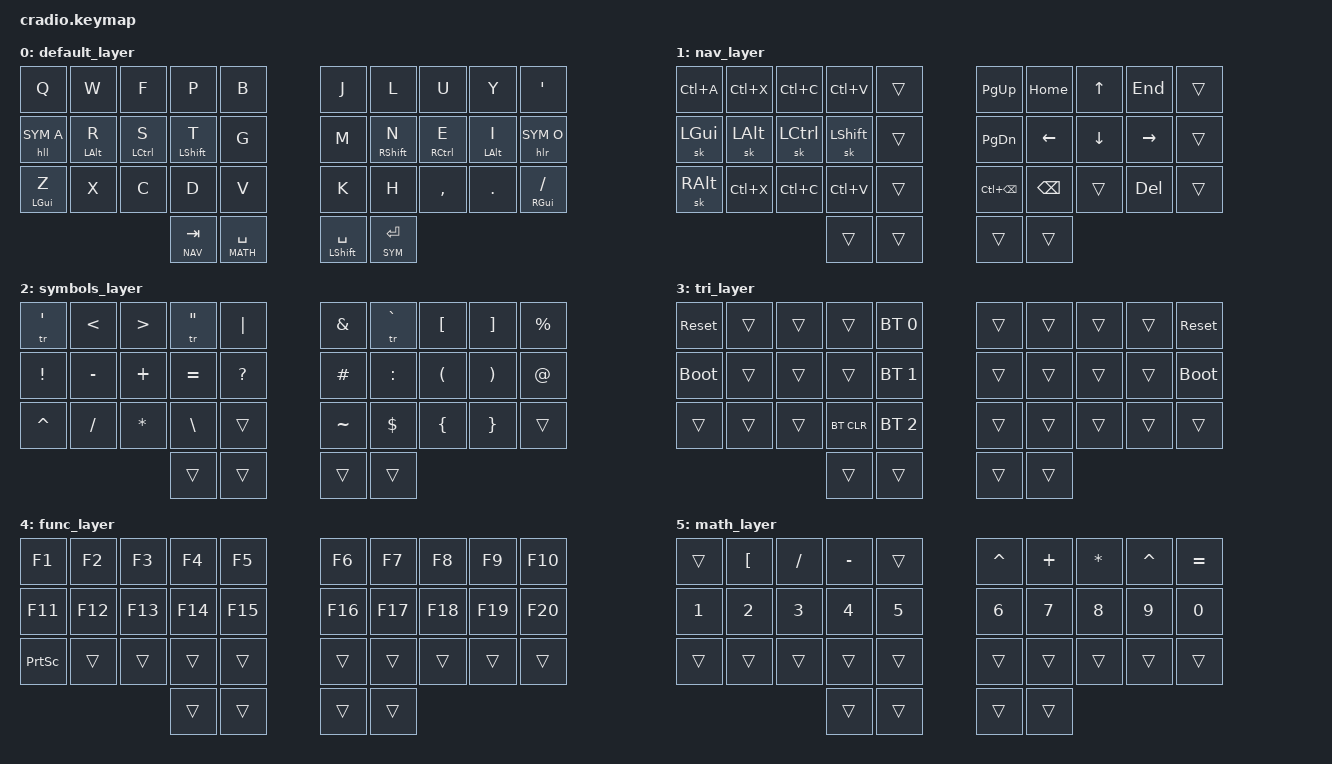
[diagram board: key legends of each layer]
// Copyright (c) 2022 The ZMK Contributors
// SPDX-License-Identifier: MIT

#include <behaviors.dtsi>
#include <dt-bindings/zmk/keys.h>
#include <dt-bindings/zmk/bt.h>
#include "timeless_hrm.keymap"
#include "zmk-helpers/key-labels/36.h" // Source key-labels.

// Home row mods macro
// #define HRML(k1,k2,k3,k4) &lt SYM   k1  &ht LALT k2  &ht LCTRL k3  &ht LSHFT k4
// #define HRMR(k1,k2,k3,k4) &ht RSHFT k1  &ht LCTRL k2  &ht LALT k3  &lt SYM k4
#define DEFAULT 0
#define NAV 1
#define SYM 2
#define TRI 3
#define FUNC 4
#define MATH 5

ZMK_COMBO(copy,  &kp LC(C), LB4 LB3)
ZMK_COMBO(paste, &kp LC(V), LB3 LB2)
ZMK_COMBO(cut, &kp LC(X), LB4 LB2)

ZMK_COMBO(esc, &kp ESC, LT3 LM3)
ZMK_COMBO(semi, &kp SEMI, RT4 RM4)
ZMK_COMBO(underscore, &kp LS(MINUS), LM3 LB3)

ZMK_COMBO(caps_wurd, &caps_word, LM1 RM1)

//ZMK_COMBO(lreset, &sys_reset, LT5 LT1)
//ZMK_COMBO(rreset, &sys_reset, RT1 RT5)

/ {
    conditional_layers {
        compatible = "zmk,conditional-layers";
        tri_layer {
            if-layers = <NAV SYM>;
            then-layer = <TRI>;
        };

        func_layer {
            if-layers = <NAV MATH>;
            then-layer = <FUNC>;
        };
    };

    // behaviors {
    //         sclh: underscore_slash {
    //             compatible = "zmk,behavior-mod-morph";
    //             #binding-cells = <0>;
    //             bindings = <LS(MINUS)>, <FSLH>;
    //             mods = <(MOD_LSFT|MOD_RSFT)>;
    //         };
    //     };

    macros {
        triple_repeat: triple_repeat {
            compatible = "zmk,behavior-macro";
            #binding-cells = <0>;
            wait-ms = <40>;
            tap-ms = <40>;
            bindings
                = <&macro_tap &key_repeat &key_repeat>;
        };

        tr: triple_ht {
            compatible = "zmk,behavior-hold-tap";
            #binding-cells = <2>;
            tapping-term-ms = <150>;
            flavor = "hold-preferred";
            bindings = <&kp>, <&triple_repeat>;
        };
    };

    keymap {
        compatible = "zmk,keymap";

        // 0
        default_layer {
            bindings = <
          //╭──────────┬──────────┬──────────┬──────────┬──────────╮   ╭──────────┬──────────┬──────────┬──────────┬──────────╮
          //│  Q       │  W       │  E       │  R       │  T       │   │  Y       │  U       │  I       │  O       │  P       │
          //├──────────┼──────────┼──────────┼──────────┼──────────┤   ├──────────┼──────────┼──────────┼──────────┼──────────┤
          //│  A       │  S       │  D       │  F       │  G       │   │  H       │  J       │  K       │  L       │ ' "      │
          //├──────────┼──────────┼──────────┼──────────┼──────────┤   ├──────────┼──────────┼──────────┼──────────┼──────────┤
          //│  Z       │  X       │  C       │  V       │  B       │   │  N       │  M       │ , <      │ . >      │ / ?      │
          //╰──────────┴──────────┴──────────┼──────────┼──────────┤   ├──────────┼──────────┼──────────┴──────────┴──────────╯
          //                                 |          |          |   |          |          |
          //                                 ╰──────────┴──────────╯   ╰──────────┴──────────╯
              &kp Q       &kp W        &kp F         &kp P         &kp B    &kp J   &kp L         &kp U         &kp Y        &kp APOS
              &hll SYM A  &hml LALT R  &hml LCTRL S  &hml LSHFT T  &kp G    &kp M   &hmr RSHFT N  &hmr RCTRL E  &hmr LALT I  &hlr SYM O
              &hml LGUI Z &kp X        &kp C         &kp D         &kp V    &kp K   &kp H         &kp COMMA     &kp DOT      &hmr RGUI FSLH
                                       &lt NAV TAB    &lt MATH SPACE        &mt LSHFT SPACE  &lt SYM ENTER
            >;
        };

        // 1
        nav_layer {
            bindings = <
          //╭──────────┬──────────┬──────────┬──────────┬──────────╮   ╭──────────┬──────────┬──────────┬──────────┬──────────╮
          //│ ALL      │  CUT     │  COPY    │  PASTE   │          │   │ HOME     │ PAGE DN  │ PAGE UP  │ END      │  :       │
          //├──────────┼──────────┼──────────┼──────────┼──────────┤   ├──────────┼──────────┼──────────┼──────────┼──────────┤
          //│ DELETE   │  4       │  5       │  6       │          │   │ LEFT     │ DOWN     │ UP       │ RIGHT    │  ;       │
          //├──────────┼──────────┼──────────┼──────────┼──────────┤   ├──────────┼──────────┼──────────┼──────────┼──────────┤
          //│ CAPS     │  7       │  8       │  9       │  0       │   │CTRL-BSPC │ BSPC     │          │ DEL      │          │
          //╰──────────┴──────────┴──────────┼──────────┼──────────┤   ├──────────┼──────────┼──────────┴──────────┴──────────╯
          //                                 |          |          |   |          |          |
          //                                 ╰──────────┴──────────╯   ╰──────────┴──────────╯
            &kp LC(A)   &kp LC(X)  &kp LC(C)  &kp LC(V)   &trans       &kp PG_UP    &kp HOME     &kp UP     &kp END     &trans
            &sk LGUI    &sk LALT   &sk LCTRL  &sk LSHFT   &trans       &kp PG_DN    &kp LEFT     &kp DOWN   &kp RIGHT   &trans
            &sk RALT    &kp LC(X)  &kp LC(C)  &kp LC(V)   &trans       &kp LC(BSPC) &kp BSPC     &trans     &kp DEL     &trans
                                              &trans      &trans       &trans       &trans
            >;
        };

        // 2
        symbols_layer {
            bindings = <
          //╭──────────┬──────────┬──────────┬──────────┬──────────╮   ╭──────────┬──────────┬──────────┬──────────┬──────────╮
          //│          │  [       │  {       │  }       │          │   │  ^       │  (       │  )       │  ]       │  ~       │
          //├──────────┼──────────┼──────────┼──────────┼──────────┤   ├──────────┼──────────┼──────────┼──────────┼──────────┤
          //│  !       │  @       │  #       │  $       │  %       │   │  *       │  -       │  =       │  \       │  `       │
          //├──────────┼──────────┼──────────┼──────────┼──────────┤   ├──────────┼──────────┼──────────┼──────────┼──────────┤
          //│          │          │          │          │          │   │  &       │  _       │  +       │  │       │          │
          //╰──────────┴──────────┴──────────┼──────────┼──────────┤   ├──────────┼──────────┼──────────┴──────────┴──────────╯
          //                                 |          |          |   |          |          |
          //                                 ╰──────────┴──────────╯   ╰──────────┴──────────╯
            &tr APOS    &kp LT      &kp GT     &tr DQT    &kp PIPE      &kp AMPERSAND   &tr GRAVE   &kp LBKT    &kp RBKT    &kp PERCENT
            &kp EXCL    &kp MINUS   &kp PLUS   &kp EQUAL  &kp QMARK     &kp HASH        &kp COLON   &kp LPAR    &kp RPAR    &kp AT_SIGN
            &kp CARET   &kp FSLH    &kp STAR   &kp BSLH   &trans        &kp TILDE       &kp DLLR    &kp LBRC    &kp RBRC    &trans
                                               &trans     &trans        &trans          &trans
            >;
        };

        // 3
        tri_layer {
            bindings = <
          //╭──────────┬──────────┬──────────┬──────────┬──────────╮   ╭──────────┬──────────┬──────────┬──────────┬──────────╮
          //│ RESET    │          │          │          │PROFILE 0 │   │          │          │          │          │  RESET   │
          //├──────────┼──────────┼──────────┼──────────┼──────────┤   ├──────────┼──────────┼──────────┼──────────┼──────────┤
          //│BOOTLOADER│          │          │          │PROFILE 1 │   │          │          │          │          │BOOTLOADER│
          //├──────────┼──────────┼──────────┼──────────┼──────────┤   ├──────────┼──────────┼──────────┼──────────┼──────────┤
          //│          │          │          │ CLEAR BT │PROFILE 2 │   │          │          │          │          │          │
          //╰──────────┴──────────┴──────────┼──────────┼──────────┤   ├──────────┼──────────┼──────────┴──────────┴──────────╯
          //                                 |          |          |   |          |          |
          //                                 ╰──────────┴──────────╯   ╰──────────┴──────────╯
            &sys_reset   &trans     &trans     &trans     &bt BT_SEL 0    &trans     &trans     &trans     &trans    &sys_reset
            &bootloader  &trans     &trans     &trans     &bt BT_SEL 1    &trans     &trans     &trans     &trans    &bootloader
            &trans       &trans     &trans    &bt BT_CLR  &bt BT_SEL 2    &trans     &trans     &trans     &trans    &trans
                                               &trans     &trans          &trans     &trans
            >;
        };

        // 4
        func_layer {
            bindings = <
            &kp F1      &kp F2      &kp F3      &kp F4      &kp F5      &kp  F6     &kp F7      &kp F8      &kp F9      &kp F10
            &kp F11     &kp F12     &kp F13     &kp F14     &kp F15     &kp  F16    &kp F17     &kp F18     &kp F19     &kp F20
            &kp PSCRN   &trans      &trans      &trans      &trans      &trans      &trans      &trans      &trans      &trans
                                                &trans      &trans      &trans      &trans
            >;
        };

        // 5
        math_layer {
            bindings = <
          //╭──────────┬──────────┬──────────┬──────────┬──────────╮   ╭──────────┬──────────┬──────────┬──────────┬──────────╮
          //│          │  [       │  {       │  }       │          │   │  ^       │  (       │  )       │  ]       │  ~       │
          //├──────────┼──────────┼──────────┼──────────┼──────────┤   ├──────────┼──────────┼──────────┼──────────┼──────────┤
          //│  !       │  @       │  #       │  $       │  %       │   │  *       │  -       │  =       │  \       │  `       │
          //├──────────┼──────────┼──────────┼──────────┼──────────┤   ├──────────┼──────────┼──────────┼──────────┼──────────┤
          //│          │          │          │          │          │   │  &       │  _       │  +       │  │       │          │
          //╰──────────┴──────────┴──────────┼──────────┼──────────┤   ├──────────┼──────────┼──────────┴──────────┴──────────╯
          //                                 |          |          |   |          |          |
          //                                 ╰──────────┴──────────╯   ╰──────────┴──────────╯
              &trans    &kp LBKT   &kp FSLH   &kp MINUS   &trans         &kp CARET  &kp PLUS   &kp STAR   &kp CARET  &kp EQUAL
              &kp N1    &kp N2     &kp N3     &kp N4      &kp N5         &kp N6     &kp N7     &kp N8     &kp N9     &kp N0
              &trans    &trans     &trans     &trans      &trans         &trans     &trans     &trans     &trans     &trans
                                              &trans      &trans         &trans     &trans
            >;
        };

    };
};
